# nrf9230_engb_isimcore register map
Vendor: Nordic Semiconductor; Series: nRF92; File version: 1
CPU: CM0 r0p1, little endian, MPU, no FPU, 2 interrupt priority bits, 32 interrupts
Registers are 32-bit, read-write, reset 0x0 unless marked. A register's access mark holds for its fields unless they carry their own. Offsets are from the block's base; [hi:lo] are bit positions; {n}, {i} and the like mark numbered series.

## CPUCONF_NS — CPU Configuration 0
Base 0x47001000
Same registers: CPUCONF_S 0x57001000
0x00 TASKS_ERASECACHE wo — Erase the caches used by the CPU.
  [0] TASKS_ERASECACHE
    1=Trigger task
0x500 INITSVTOR — Initial value of the secure VTOR (Vector Table Offset Register) after CPU reset.
  [31:0] INITSVTOR — Initial value of the VTOR.
0x504 INITNSVTOR — Initial value of the non-secure VTOR (Vector Table Offset Register).
  [31:0] INITNSVTOR — Initial value of the VTOR.
0x508 CPUSTART — Enable for starting the CPU
  [0] EN — Enable to start the CPU.
    0=Stopped (CPU stopped.); 1=Started (CPU started.)
0x50C CPUWAIT — Enable for the CPU wait.
  [0] EN — Enable to the CPU wait.
    0=Disabled (CPU is not waiting.); 1=Enabled (CPU is waiting.)

## PCGCM0_S — PCGC Master 0
Base 0x57004000
Same registers: PCGCM1_S 0x57014000
{0xE0+4i} SETPWRCONTHRESHOLDBASE[{i}] (i=0..2) — Description collection: Set power consumption threshold base for power source / regulator n
  [3:0] SETPWRCONTHRESHOLDBASE
0xC00 UNLOCKBACKDOORS
  [15:0] UNLOCKBACKDOORS — Write: 0x00009375 to lock/unlock backdoors Read: 0x00000001 if backdoors is enabled Read: 0x00000000 if backdoors is disabled
0xC04 ENABLEPOWERREGFORCE
  [2:0] ENABLEPOWERREGFORCE
0xC08 POWERREGFORCE — Force reg
  [2:0] POWERREGFORCEREG
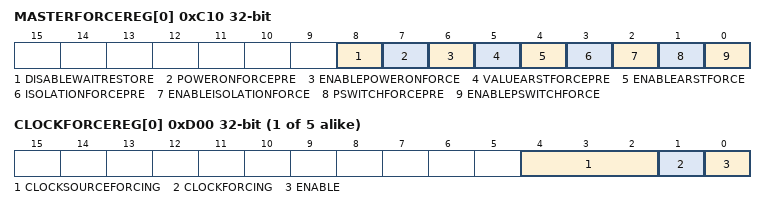
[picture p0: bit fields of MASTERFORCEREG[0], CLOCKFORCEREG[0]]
{0xC10+4i} MASTERFORCEREG[{i}] (i=0..0) — Description collection: Force reg
  [8] DISABLEWAITRESTORE — Turn off waiting for arst deactivation before retention restore
    1=Disable (Turn off waiting for arst deactivation before retention restore); 0=Enable (Wait for arst deactivation before retention restore)
  [7] POWERONFORCEPRE
  [6] ENABLEPOWERONFORCE
  [5] VALUEARSTFORCEPRE
  [4] ENABLEARSTFORCE
  [3] ISOLATIONFORCEPRE
  [2] ENABLEISOLATIONFORCE
  [1] PSWITCHFORCEPRE
  [0] ENABLEPSWITCHFORCE
{0xD00+4i} CLOCKFORCEREG[{i}] (i=0..4) — Description collection: Force clock n
  [4:2] CLOCKSOURCEFORCING
  [1] CLOCKFORCING
  [0] ENABLE — Enable clock forcing

## PCGCS0_S — PCGCSlave 0
Base 0x57005000
Same registers: PCGCS1_S 0x57015000, PCGCS2_S 0x57026000
{0xC00+4i} PENALTY[{i}] (i=0..1) reset 0xFFFFFFFC — Description collection: Penalty level for power/clock pair n. When FULL_PCP_ZERO feature is not supported, PENALTY[0] address overlaps the PENALTY0 address and register description for PENALTY[0] is not valid.
  [1:0] PENALTY — Penalty level
0xC00 PENALTY0 (alternate view of PENALTY[*]) — Penalty level for power/clock pair 0. The register description is valid only when FULL_PCP_ZERO feature is not supported
  [1:0] PENALTY ro — Penalty level
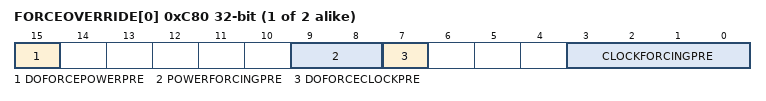
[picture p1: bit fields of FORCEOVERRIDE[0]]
{0xC80+4i} FORCEOVERRIDE[{i}] (i=0..1) — Description collection: Force override of power/clock pair n.
  [15] DOFORCEPOWERPRE, [9:8] POWERFORCINGPRE, [7] DOFORCECLOCKPRE, [3:0] CLOCKFORCINGPRE

## MHU0SND_NS — Message handling unit sender (MHUSND) 0
Base 0x47021000
Same registers: MHU1SND_NS 0x47023000, MHU0SND_S 0x57021000, MHU1SND_S 0x57023000
{0x0+0x20*i} REG_{i}_STAT ro (i=0..7) — Sender message status register before the mask
{0xC+0x20*i} REG_{i}_STAT_SET wo (i=0..7) — Sender message set status register
0xF80 MSG_NO_CAP wo reset 0x8 — Sender control register for number of message communication channels configured, between 1 and 124
  [6:0] MSG_NO_CAP — Number of message communication channels
0xF84 RESP_CFG wo — Sender control register for receiver power down error response control
  [0] RESP_CFG — Receiver power down error response control
    0=NoError (Do not return slave error); 1=Error (Return slave error)
0xF88 ACCESS_REQUEST wo — Sender control register for sending access request to receiver
  [0] ACCESS_REQUEST — Receiver access request
    0=NoRequest; 1=Request (Send request)
0xF8C ACCESS_READY ro — Sender control register for receiver status
  [0] ACCESS_READY — Receiver status
    0=NotReady (Receiver not ready to respond); 1=Ready (Receiver ready to respond)
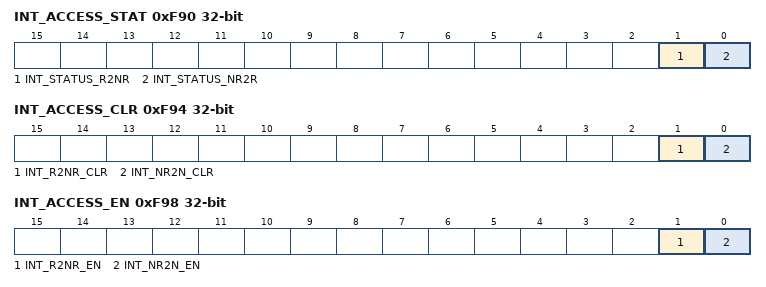
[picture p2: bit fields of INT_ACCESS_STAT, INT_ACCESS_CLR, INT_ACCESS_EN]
0xF90 INT_ACCESS_STAT ro — Sender register for receiver ACCESS_READY interrupt status
  [1] INT_STATUS_R2NR — ACCESS_READY interrupt status for ready to not ready (R2NR) transition
    0=NotPending (No R2NR transition detected); 1=Pending (R2NR transition detected)
  [0] INT_STATUS_NR2R — ACCESS_READY interrupt status for not ready to ready (NR2R) transition
    0=NotPending (No NR2R transition detected); 1=Pending (NR2R transition detected)
0xF94 INT_ACCESS_CLR wo — Sender control register for clearing INT_ACCESS_STAT interrupts
  [1] INT_R2NR_CLR — Interrupt R2NR clear register
    0=NoAction; 1=Clear INT_ACCESS_STAT R2NR interrupt
  [0] INT_NR2N_CLR — Interrupt NR2N clear register
    0=NoAction; 1=Clear INT_ACCESS_STAT NR2R interrupt
0xF98 INT_ACCESS_EN wo — Sender control register for masking INT_ACCESS_STAT interrupts
  [1] INT_R2NR_EN — Interrupt mask register
    0=Mask INT_ACCESS_STAT R2NR interrupt; 1=Enable INT_ACCESS_STAT R2NR interrupt
  [0] INT_NR2N_EN — Interrupt mask register
    0=Mask INT_ACCESS_STAT NR2R interrupt; 1=Enable INT_ACCESS_STAT NR2R interrupt
0x1F6C PID4 ro reset 0x4 — Receiver Peripheral ID 4
  [7:0] PID4 — Sender Peripheral ID 4
0x1F7C PID0 ro reset 0xD1 — Receiver Peripheral ID 0
  [7:0] PID0 — Sender Peripheral ID 0
0x1F80 PID1 ro reset 0xB0 — Receiver Peripheral ID 1
  [7:0] PID1 — Sender Peripheral ID 1
0x1F84 PID2 ro reset 0xB — Receiver Peripheral ID 2
  [7:0] PID2 — Sender Peripheral ID 2
0x1F88 PID3 ro — Receiver Peripheral ID 3
  [7:0] PID3 — Sender Peripheral ID 3
0x1F8C COMPID0 ro reset 0xD — Component ID 0
  [7:0] COMPID0
0x1F90 COMPID1 ro reset 0xF0 — Component ID 1
  [7:0] COMPID1
0x1F94 COMPID2 ro reset 0x5 — Component ID 2
  [7:0] COMPID2
0x1F98 COMPID3 ro reset 0xB1 — Component ID 3
  [7:0] COMPID3

## Notices in the file
Copyright (c) 2010 - 2024, Nordic Semiconductor ASA
All rights reserved.
Redistribution and use in source and binary forms, with or without modification,
are permitted provided that the following conditions are met:
1. Redistributions of source code must retain the above copyright notice, this
list of conditions and the following disclaimer.
2. Redistributions in binary form, except as embedded into a Nordic
Semiconductor ASA integrated circuit in a product or a software update for
such product, must reproduce the above copyright notice, this list of
conditions and the following disclaimer in the documentation and/or other
materials provided with the distribution.
3. Neither the name of Nordic Semiconductor ASA nor the names of its
contributors may be used to endorse or promote products derived from this
software without specific prior written permission.
4. This software, with or without modification, must only be used with a
Nordic Semiconductor ASA integrated circuit.
5. Any software provided in binary form under this license must not be reverse
engineered, decompiled, modified and/or disassembled.
THIS SOFTWARE IS PROVIDED BY NORDIC SEMICONDUCTOR ASA "AS IS" AND ANY EXPRESS
OR IMPLIED WARRANTIES, INCLUDING, BUT NOT LIMITED TO, THE IMPLIED WARRANTIES
OF MERCHANTABILITY, NONINFRINGEMENT, AND FITNESS FOR A PARTICULAR PURPOSE ARE
DISCLAIMED. IN NO EVENT SHALL NORDIC SEMICONDUCTOR ASA OR CONTRIBUTORS BE
LIABLE FOR ANY DIRECT, INDIRECT, INCIDENTAL, SPECIAL, EXEMPLARY, OR
CONSEQUENTIAL DAMAGES (INCLUDING, BUT NOT LIMITED TO, PROCUREMENT OF SUBSTITUTE
GOODS OR SERVICES; LOSS OF USE, DATA, OR PROFITS; OR BUSINESS INTERRUPTION)
HOWEVER CAUSED AND ON ANY THEORY OF LIABILITY, WHETHER IN CONTRACT, STRICT
LIABILITY, OR TORT (INCLUDING NEGLIGENCE OR OTHERWISE) ARISING IN ANY WAY OUT
OF THE USE OF THIS SOFTWARE, EVEN IF ADVISED OF THE POSSIBILITY OF SUCH DAMAGE.
